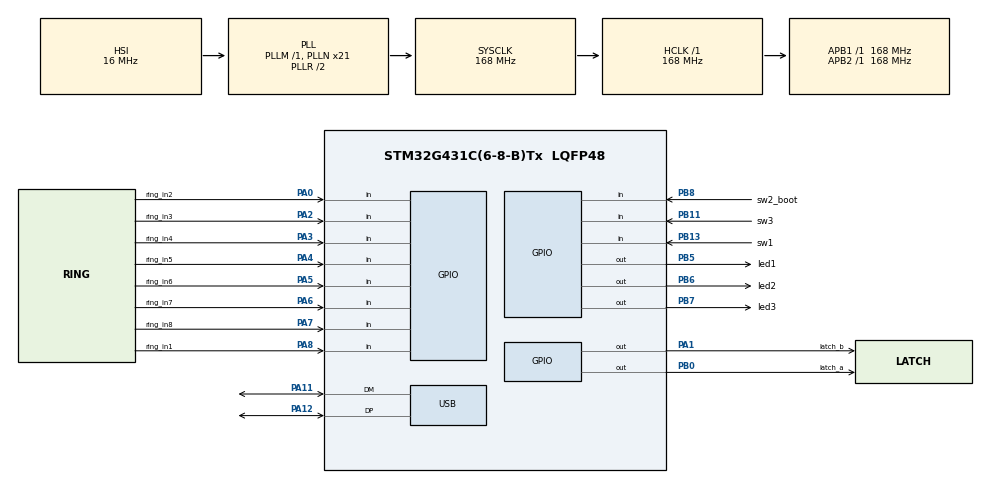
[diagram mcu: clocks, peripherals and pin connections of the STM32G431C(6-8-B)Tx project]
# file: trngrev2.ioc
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Mcu.Family=STM32G4
Mcu.Name=STM32G431C(6-8-B)Tx
Mcu.Package=LQFP48
NVIC.PriorityGroup=NVIC_PRIORITYGROUP_4
NVIC.TIM6_DAC_IRQn=true\:0\:0\:false\:false\:true\:true\:false\:true
NVIC.USB_LP_IRQn=true\:3\:0\:true\:false\:true\:false\:true\:true
PA0.GPIO_Label=ring_in2
PA0.Signal=GPIO_Input
PA1.GPIO_Label=latch_b
PA1.GPIO_Speed=GPIO_SPEED_FREQ_VERY_HIGH
PA1.Signal=GPIO_Output
PA11.Mode=Device
PA11.Signal=USB_DM
PA12.Mode=Device
PA12.Signal=USB_DP
PA13.Signal=SYS_JTMS-SWDIO
PA14.Signal=SYS_JTCK-SWCLK
PA2.GPIO_Label=ring_in3
PA2.Signal=GPIO_Input
PA3.GPIO_Label=ring_in4
PA3.Signal=GPIO_Input
PA4.GPIO_Label=ring_in5
PA4.Signal=GPIO_Input
PA5.GPIO_Label=ring_in6
PA5.Signal=GPIO_Input
PA6.GPIO_Label=ring_in7
PA6.Signal=GPIO_Input
PA7.GPIO_Label=ring_in8
PA7.Signal=GPIO_Input
PA8.GPIO_Label=ring_in1
PA8.Signal=GPIO_Input
PB0.GPIO_Label=latch_a
PB0.GPIO_Speed=GPIO_SPEED_FREQ_VERY_HIGH
PB0.Signal=GPIO_Output
PB11.GPIO_Label=sw3
PB11.GPIO_PuPd=GPIO_PULLDOWN
PB11.Signal=GPIO_Input
PB13.GPIO_Label=sw1
PB13.GPIO_PuPd=GPIO_PULLDOWN
PB13.Signal=GPIO_Input
PB5.GPIO_Label=led1
PB5.Signal=GPIO_Output
PB6.GPIO_Label=led2
PB6.Signal=GPIO_Output
PB7.GPIO_Label=led3
PB7.GPIO_Speed=GPIO_SPEED_FREQ_LOW
PB7.PinState=GPIO_PIN_RESET
PB7.Signal=GPIO_Output
PB8-BOOT0.GPIO_Label=sw2_boot
PB8-BOOT0.GPIO_PuPd=GPIO_PULLDOWN
PB8-BOOT0.Signal=GPIO_Input
ProjectManager.HeapSize=0x200
ProjectManager.StackSize=0x400
ProjectManager.TargetToolchain=STM32CubeIDE
TIM6.Period=559
TIM6.Prescaler=0
RCC.ADC12Freq_Value=168000000
RCC.AHBFreq_Value=168000000
RCC.APB1Freq_Value=168000000
RCC.APB1TimFreq_Value=168000000
RCC.APB2Freq_Value=168000000
RCC.APB2TimFreq_Value=168000000
RCC.CK48CLockSelection=RCC_USBCLKSOURCE_HSI48
RCC.CortexFreq_Value=168000000
RCC.EXTERNAL_CLOCK_VALUE=12288000
RCC.HCLKFreq_Value=168000000
RCC.HSE_VALUE=8000000
RCC.HSI48_VALUE=48000000
RCC.HSI_VALUE=16000000
RCC.LSE_VALUE=32768
RCC.PLLN=21
RCC.SYSCLKFreq_VALUE=168000000
RCC.SYSCLKSource=RCC_SYSCLKSOURCE_PLLCLK
RCC.USBFreq_Value=48000000
RCC.VCOOutputFreq_Value=336000000
USB_DEVICE.APP_RX_DATA_SIZE=64
USB_DEVICE.APP_TX_DATA_SIZE=64
USB_DEVICE.CLASS_NAME_FS=CDC
USB_DEVICE.MANUFACTURER_STRING=TheTosters
USB_DEVICE.PRODUCT_STRING_CDC_FS=Toster TRNG v2
USB_DEVICE.USBD_SELF_POWERED=0
USB_DEVICE.VirtualMode=Cdc
USB_DEVICE.VirtualModeFS=Cdc_FS
VP_SYS_VS_DBSignals.Mode=DisableDeadBatterySignals
VP_TIM6_VS_ClockSourceINT.Mode=Enable_Timer
VP_USB_DEVICE_VS_USB_DEVICE_CDC_FS.Mode=CDC_FS
board=custom

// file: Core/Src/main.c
/* USER CODE BEGIN Header */
/**
  ******************************************************************************
  * @file           : main.c
  * @brief          : Main program body
  ******************************************************************************
  * @attention
  *
  * Copyright (c) 2026 STMicroelectronics.
  * All rights reserved.
  *
  * This software is licensed under terms that can be found in the LICENSE file
  * in the root directory of this software component.
  * If no LICENSE file comes with this software, it is provided AS-IS.
  *
  ******************************************************************************
  */
/* USER CODE END Header */
#include "main.h"
#include "usb_device.h"

/* USER CODE BEGIN Includes */
#include "entropy_collector.h"
#include "sender.h"
#include "haptic.h"
#include "buttons.h"
/* USER CODE END Includes */

TIM_HandleTypeDef htim6;

void SystemClock_Config(void);
static void MX_GPIO_Init(void);
static void MX_TIM6_Init(void);

int main(void)
{

  /* MCU Configuration--------------------------------------------------------*/

  /* Reset of all peripherals, Initializes the Flash interface and the Systick. */
  HAL_Init();

  /* Configure the system clock */
  SystemClock_Config();

  /* Initialize all configured peripherals */
  MX_GPIO_Init();
  MX_TIM6_Init();
  MX_USB_Device_Init();
  /* USER CODE BEGIN 2 */

  loadConfiguration();
  HAL_TIM_Base_Start_IT(&htim6);
  /* USER CODE END 2 */

  /* Infinite loop */
	while (1) {

		/* USER CODE BEGIN 3 */
		//look also into usbd_cdc_if.c method CDC_Receive_FS
		//and stm32g4xx_it.c method TIM6_DAC_IRQHandler
		buttonsUpdate();
		if (buttonPressed(BUTTON_SELF_TEST)) {
			startSelfTest();
		}
		if (buttonPressed(BUTTON_RESTART)) {
			restartAcquisition();
		}
		updateCollector();
		updateSender();
		ledUpdate();
	}
  /* USER CODE END 3 */
}

void SystemClock_Config(void)
{
  RCC_OscInitTypeDef RCC_OscInitStruct = {0};
  RCC_ClkInitTypeDef RCC_ClkInitStruct = {0};

  /** Configure the main internal regulator output voltage
  */
  HAL_PWREx_ControlVoltageScaling(PWR_REGULATOR_VOLTAGE_SCALE1_BOOST);

  /** Initializes the RCC Oscillators according to the specified parameters
  * in the RCC_OscInitTypeDef structure.
  */
  RCC_OscInitStruct.OscillatorType = RCC_OSCILLATORTYPE_HSI|RCC_OSCILLATORTYPE_HSI48;
  RCC_OscInitStruct.HSIState = RCC_HSI_ON;
  RCC_OscInitStruct.HSICalibrationValue = RCC_HSICALIBRATION_DEFAULT;
  RCC_OscInitStruct.HSI48State = RCC_HSI48_ON;
  RCC_OscInitStruct.PLL.PLLState = RCC_PLL_ON;
  RCC_OscInitStruct.PLL.PLLSource = RCC_PLLSOURCE_HSI;
  RCC_OscInitStruct.PLL.PLLM = RCC_PLLM_DIV1;
  RCC_OscInitStruct.PLL.PLLN = 21;
  RCC_OscInitStruct.PLL.PLLP = RCC_PLLP_DIV2;
  RCC_OscInitStruct.PLL.PLLQ = RCC_PLLQ_DIV2;
  RCC_OscInitStruct.PLL.PLLR = RCC_PLLR_DIV2;
  if (HAL_RCC_OscConfig(&RCC_OscInitStruct) != HAL_OK)
  {
    Error_Handler();
  }

  /** Initializes the CPU, AHB and APB buses clocks
  */
  RCC_ClkInitStruct.ClockType = RCC_CLOCKTYPE_HCLK|RCC_CLOCKTYPE_SYSCLK
                              |RCC_CLOCKTYPE_PCLK1|RCC_CLOCKTYPE_PCLK2;
  RCC_ClkInitStruct.SYSCLKSource = RCC_SYSCLKSOURCE_PLLCLK;
  RCC_ClkInitStruct.AHBCLKDivider = RCC_SYSCLK_DIV1;
  RCC_ClkInitStruct.APB1CLKDivider = RCC_HCLK_DIV1;
  RCC_ClkInitStruct.APB2CLKDivider = RCC_HCLK_DIV1;

  if (HAL_RCC_ClockConfig(&RCC_ClkInitStruct, FLASH_LATENCY_4) != HAL_OK)
  {
    Error_Handler();
  }
}

static void MX_TIM6_Init(void)
{

  TIM_MasterConfigTypeDef sMasterConfig = {0};

  /* USER CODE BEGIN TIM6_Init 1 */
  //The value below is only what the timer starts with: loadConfiguration() in
	//USER CODE 2 overrides ARR from sampling_arr[] in entropy_collector.c before
	//the timer is started, and the 't' command changes it at runtime.
	//Keep this in step with sampling_arr[DEFAULT_SAMPLING_INDEX] so a build with
	//an erased config still comes up at the chosen 300 kHz (ARR 559).
  /* USER CODE END TIM6_Init 1 */
  htim6.Instance = TIM6;
  htim6.Init.Prescaler = 0;
  htim6.Init.CounterMode = TIM_COUNTERMODE_UP;
  htim6.Init.Period = 559;
  htim6.Init.AutoReloadPreload = TIM_AUTORELOAD_PRELOAD_DISABLE;
  if (HAL_TIM_Base_Init(&htim6) != HAL_OK)
  {
    Error_Handler();
  }
  sMasterConfig.MasterOutputTrigger = TIM_TRGO_RESET;
  sMasterConfig.MasterSlaveMode = TIM_MASTERSLAVEMODE_DISABLE;
  if (HAL_TIMEx_MasterConfigSynchronization(&htim6, &sMasterConfig) != HAL_OK)
  {
    Error_Handler();
  }

}

static void MX_GPIO_Init(void)
{
  GPIO_InitTypeDef GPIO_InitStruct = {0};

  /* GPIO Ports Clock Enable */
  __HAL_RCC_GPIOA_CLK_ENABLE();
  __HAL_RCC_GPIOB_CLK_ENABLE();

  /*Configure GPIO pin Output Level */
  HAL_GPIO_WritePin(latch_b_GPIO_Port, latch_b_Pin, GPIO_PIN_RESET);

  /*Configure GPIO pin Output Level */
  HAL_GPIO_WritePin(GPIOB, latch_a_Pin|led1_Pin|led2_Pin|led3_Pin, GPIO_PIN_RESET);

  /*Configure GPIO pins : ring_in2_Pin ring_in3_Pin ring_in4_Pin ring_in5_Pin
                           ring_in6_Pin ring_in7_Pin ring_in8_Pin ring_in1_Pin */
  GPIO_InitStruct.Pin = ring_in2_Pin|ring_in3_Pin|ring_in4_Pin|ring_in5_Pin
                          |ring_in6_Pin|ring_in7_Pin|ring_in8_Pin|ring_in1_Pin;
  GPIO_InitStruct.Mode = GPIO_MODE_INPUT;
  GPIO_InitStruct.Pull = GPIO_NOPULL;
  HAL_GPIO_Init(GPIOA, &GPIO_InitStruct);

  /*Configure GPIO pin : latch_b_Pin */
  GPIO_InitStruct.Pin = latch_b_Pin;
  GPIO_InitStruct.Mode = GPIO_MODE_OUTPUT_PP;
  GPIO_InitStruct.Pull = GPIO_NOPULL;
  GPIO_InitStruct.Speed = GPIO_SPEED_FREQ_VERY_HIGH;
  HAL_GPIO_Init(latch_b_GPIO_Port, &GPIO_InitStruct);

  /*Configure GPIO pin : latch_a_Pin */
  GPIO_InitStruct.Pin = latch_a_Pin;
  GPIO_InitStruct.Mode = GPIO_MODE_OUTPUT_PP;
  GPIO_InitStruct.Pull = GPIO_NOPULL;
  GPIO_InitStruct.Speed = GPIO_SPEED_FREQ_VERY_HIGH;
  HAL_GPIO_Init(latch_a_GPIO_Port, &GPIO_InitStruct);

  /*Configure GPIO pins : sw3_Pin sw1_Pin sw2_boot_Pin */
  GPIO_InitStruct.Pin = sw3_Pin|sw1_Pin|sw2_boot_Pin;
  GPIO_InitStruct.Mode = GPIO_MODE_INPUT;
  GPIO_InitStruct.Pull = GPIO_PULLDOWN;
  HAL_GPIO_Init(GPIOB, &GPIO_InitStruct);

  /*Configure GPIO pins : led1_Pin led2_Pin led3_Pin */
  GPIO_InitStruct.Pin = led1_Pin|led2_Pin|led3_Pin;
  GPIO_InitStruct.Mode = GPIO_MODE_OUTPUT_PP;
  GPIO_InitStruct.Pull = GPIO_NOPULL;
  GPIO_InitStruct.Speed = GPIO_SPEED_FREQ_LOW;
  HAL_GPIO_Init(GPIOB, &GPIO_InitStruct);

}

void Error_Handler(void)
{
  __disable_irq();
  while (1)
  {
  }
}
